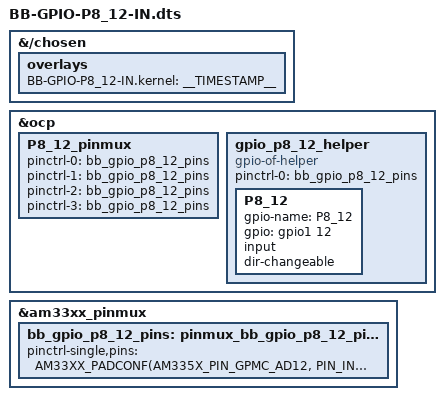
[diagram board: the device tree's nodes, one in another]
// SPDX-License-Identifier: GPL-2.0-only
/*
 * Copyright (C) 2025 Custom
 * Virtual cape for GPIO input on connector pin P8.12
 *
 *
 *
```
vim /opt/source/dtb-5.10-ti/src/arm/overlays/BB-GPIO-P8_12-00A0.dts
cd /opt/source/dtb-5.10-ti/
make all

# Copy to firmware
sudo cp BB-GPIO-P8_12-00A0.dtbo /lib/firmware/

# Edit /boot/uEnv.txt
    cape_universal=enable
    ###Additional custom capes
    uboot_overlay_addr0=/lib/firmware/BB-GPIO-P8_12-00A0.dts



# reboot


########### Check: via pinctrl

sudo cat /sys/kernel/debug/pinctrl/44e10800.pinmux-pinctrl-single/pins | grep "pin 12"

    pin 12 (PIN12) 12:gpio-32-63 44e10830 00000037 pinctrl-single

    The register value is 0x00000037. Let me decode this:
    Decoding 0x37 (PIN12 Register Value)
    0x37 = 0011 0111 in binary

    Bit breakdown:
        Bit 5 (0x20): 1 = INPUT ✓
        Bit 4 (0x10): 1 = PULLUP enabled ✓
        Bit 3 (0x08): 0 = PULLDOWN disabled
        Bits 2-0 (0x07): 111 = MODE 7 (GPIO) ✓



########### Check: via sysfs

echo 44 > /sys/class/gpio/export
cat /sys/class/gpio/gpio44/direction


########### Check: via libgpiod

root@BeagleBone:~# gpiodetect
gpiochip0 [gpio-0-31] (32 lines)
gpiochip1 [gpio-32-63] (32 lines)
gpiochip2 [gpio-64-95] (32 lines)
gpiochip3 [gpio-96-127] (32 lines)
root@BeagleBone:~# gpioinfo gpiochip1
gpiochip1 - 32 lines:
        line   0: "P8_25 [mmc1_dat0]" "P8_25" input active-high [used]
        line   1: "[mmc1_dat1]" "P8_24" input active-high [used]
        line   2: "P8_5 [mmc1_dat2]" "P8_05" input active-high [used]
        line   3: "P8_6 [mmc1_dat3]" "P8_06" input active-high [used]
        line   4: "P8_23 [mmc1_dat4]" "P8_23" input active-high [used]
        line   5: "P8_22 [mmc1_dat5]" "P8_22" input active-high [used]
        line   6: "P8_3 [mmc1_dat6]" "P8_03" input active-high [used]
        line   7: "P8_4 [mmc1_dat7]" "P8_04" input active-high [used]
        line   8:         "NC"  "PHY reset"  output   active-low [used]
        line   9:         "NC"       unused   input  active-high
        line  10:         "NC"       unused   input  active-high
        line  11:         "NC"       unused   input  active-high
        line  12:      "P8_12"      "P8_12"   input  active-high [used] <<<<<<<<
        line  13:      "P8_11"      "P8_11"   input  active-high [used]
        line  14:      "P8_16"      "P8_16"   input  active-high [used]
        line  15:      "P8_15"      "P8_15"   input  active-high [used]
        line  16:     "P9_15A"      "P9_15"   input  active-high [used]
        line  17:      "P9_23"      "P9_23"   input  active-high [used]
        line  18: "P9_14 [ehrpwm1a]" "P9_14" input active-high [used]
        line  19: "P9_16 [ehrpwm1b]" "P9_16" input active-high [used]
        line  20: "[emmc rst]"       unused   input  active-high
        line  21: "[usr0 led]" "beaglebone:green:usr0" output active-high [used]
        line  22: "[usr1 led]" "beaglebone:green:usr1" output active-high [used]
        line  23: "[usr2 led]" "beaglebone:green:usr2" output active-high [used]
        line  24: "[usr3 led]" "beaglebone:green:usr3" output active-high [used]
        line  25: "[hdmi irq]"  "interrupt"   input  active-high [used]
        line  26: "[usb vbus oc]" unused input active-high
        line  27: "[hdmi audio]" "enable" output active-high [used]
        line  28:      "P9_12"      "P9_12"   input  active-high [used]
        line  29:      "P8_26"      "P8_26"   input  active-high [used]
        line  30: "P8_21 [emmc]" "P8_21" input active-high [used]
        line  31: "P8_20 [emmc]" "P8_20" input active-high [used]




 ```
 *
 *
 */
/*
 * Helper to show loaded overlays under: /proc/device-tree/chosen/overlays/
 */
&{/chosen} {
        overlays {
                BB-GPIO-P8_12-IN.kernel = __TIMESTAMP__;
        };
};

/*
 * Override the default pinmux state for P8_12
 */
&ocp {
        P8_12_pinmux {
                /* Keep pinmux helper enabled but override the state */
                pinctrl-names = "default", "gpio", "gpio_pu", "gpio_pd";
                pinctrl-0 = <&bb_gpio_p8_12_pins>;  /* default state */
                pinctrl-1 = <&bb_gpio_p8_12_pins>;  /* gpio state */
                pinctrl-2 = <&bb_gpio_p8_12_pins>;  /* gpio_pu state */
                pinctrl-3 = <&bb_gpio_p8_12_pins>;  /* gpio_pd state */
        };
};

&am33xx_pinmux {
        bb_gpio_p8_12_pins: pinmux_bb_gpio_p8_12_pins {
                pinctrl-single,pins = <
                        AM33XX_PADCONF(AM335X_PIN_GPMC_AD12, PIN_INPUT_PULLUP, MUX_MODE7)  /* P8_12 (T12) gpmc_ad12.gpio1_12 */
                >;
        };
};

&ocp {
        gpio_p8_12_helper: gpio_p8_12_helper {
                compatible = "gpio-of-helper";
                status = "okay";
                pinctrl-names = "default";
                pinctrl-0 = <&bb_gpio_p8_12_pins>;

                P8_12 {
                        gpio-name = "P8_12";
                        gpio = <&gpio1 12 0>;
                        input;
                        dir-changeable;
                };
        };
};

